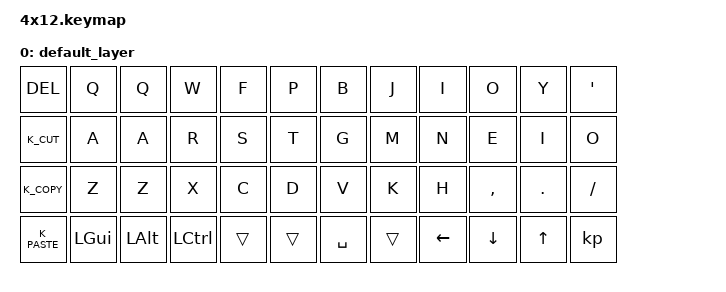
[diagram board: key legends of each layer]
#include <behaviors.dtsi>
#include <dt-bindings/zmk/keys.h>

#define DEFAULT 0
#define LOWER   1
#define RAISE   2
#define RAISE   3

/ {
	keymap {
		compatible = "zmk,keymap";

		default_layer {
// -----------------------------------------------------------------------------------------
// |  DEL  |  Q   |  Q   |  W   |  F   |  P   |   B   |  J    |  L   |  U   |   Y   |  '    |
// |  K_CUT|  A   |  A   |  R   |  S   |  T   |   G   |  M    |  N   |  E   |   I   |  O    |
// | K_COPY|  Z   |  Z   |  X   |  C   |  D   |   V   |  K    |  ,   | COMMA|   DOT |  /    |
// | K_PASTE| LCTL | PSCRN| LALT | LOWR | SHIFT| SPACE|  RAIS | LARW | DARW |   -   |  ;    |
			bindings = <
	DEL   &kp Q    &kp Q    &kp W     &kp F  &kp P  &kp B     &kp J  &kp I     &kp O    &kp Y    &kp SQT
	K_CUT   &kp A    &kp A    &kp R     &kp S  &kp T  &kp G     &kp M  &kp N     &kp E    &kp I    &kp O
	K_COPY &kp Z    &kp Z    &kp X     &kp C  &kp D  &kp V     &kp K  &kp H     &kp COMMA &kp DOT &kp /
	K_PASTE &kp LGUI &kp LALT &kp LCTRL &trans &trans &kp SPACE &trans &kp LEFT  &kp DOWN &kp UP   &kp ;
			>;
		};
		
		




		
		
	};
};


